# G32R501 register map
Vendor: Geehy Semiconductor Co., Ltd.; Series: G32R5; File version: 1.0
CPU: CM55 r0p1, little endian, MPU, FPU, double-precision FPU, DSP, VTOR, 4 interrupt priority bits
Registers are 32-bit, read-write, reset 0x0 unless marked. A register's access mark holds for its fields unless they carry their own. Offsets are from the block's base; [hi:lo] are bit positions; {n}, {i} and the like mark numbered series.

## PWM_SYNC_SOC
Base 0x40030C80
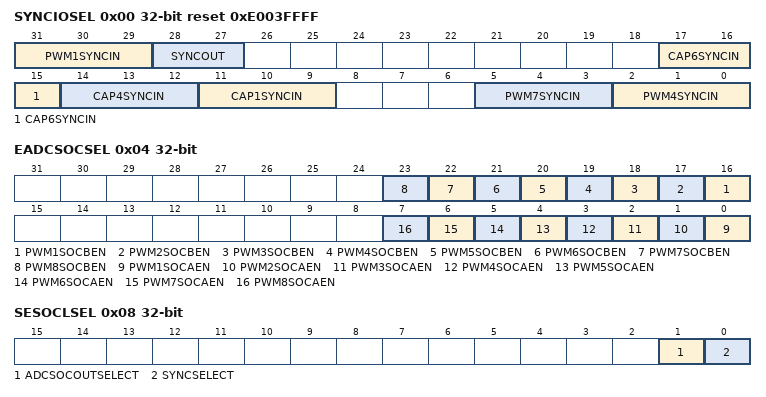
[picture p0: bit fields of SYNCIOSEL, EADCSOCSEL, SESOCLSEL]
0x00 SYNCIOSEL reset 0xE003FFFF
  [31:29] PWM1SYNCIN — PWM1 Sync Input Source Select
  [28:27] SYNCOUT — Sync Output Source Select
  [17:15] CAP6SYNCIN — CAP6 Sync Input Source Select
  [14:12] CAP4SYNCIN — CAP4 Sync Input Source Select
  [11:9] CAP1SYNCIN — CAP1 Sync Input Source Select
  [5:3] PWM7SYNCIN — PWM7 Sync Input Source Select
  [2:0] PWM4SYNCIN — PWM4 Sync Input Source Select
0x04 EADCSOCSEL
  [n+15] PWM{n}SOCBEN (n=1..8) — PWM{n} SOCB Output Source Select
  [n-1] PWM{n}SOCAEN (n=1..8) — PWM{n} SOCA Output Source Select
0x08 SESOCLSEL
  [1] ADCSOCOUTSELECT — EADCSOCSEL Lock
  [0] SYNCSELECT — SIOSEL Lock

## CAP1 — Enhanced capture (CAP) module
Base 0x40002000
Same registers: CAP2 0x40002400, CAP3 0x40002800, CAP4 0x40002C00, CAP5 0x40003000, CAP6 0x40003400, CAP7 0x40003800
0x00 TSCTR — Time-Stamp Counter
  [31:0] TSCTR — Active 32-bit counter register that is used as the capture time-base HR mode
0x04 CTRPHS — Counter Phase Offset Value Register
  [31:0] CTRPHS — Counter phase value register that can be programmed for phase lag/lead
{0x4+4i} CAP{i} (i=1..4) — Capture {i} Register
0x24 ECCTL0 reset 0x7F — Capture Control Register 0
  [6:0] INPUTSEL — Capture input source select bits
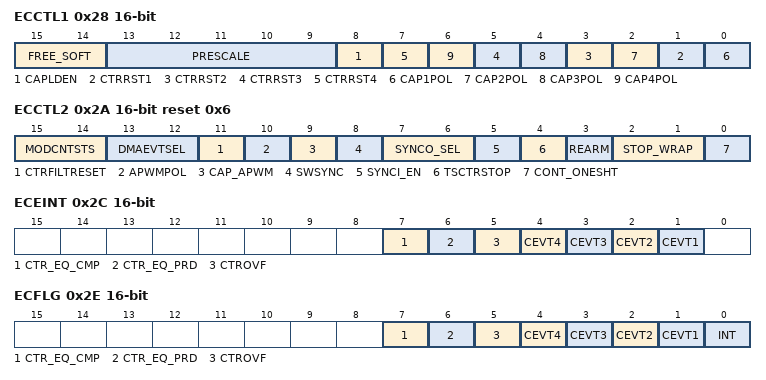
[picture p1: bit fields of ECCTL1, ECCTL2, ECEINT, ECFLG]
0x28 ECCTL1 16-bit — Capture Control Register 1
  [15:14] FREE_SOFT — Emulation Control
  [13:9] PRESCALE — Event Filter prescale select
  [8] CAPLDEN — Enable loading of CAP1-4 registers on a capture event
  [2n-1] CTRRST{n} (n=1..4) — Counter Reset on Capture Event {n}
  [2n-2] CAP{n}POL (n=1..4) — Capture Event {n} Polarity select
0x2A ECCTL2 16-bit access per field reset 0x6 — Capture Control Register 2
  [15:14] MODCNTSTS ro — This bit field reads current status on modulo counter
  [13:12] DMAEVTSEL rw — DMA event select
  [11] CTRFILTRESET rw — Reset Bit
  [10] APWMPOL rw — APWM output polarity select
  [9] CAP_APWM rw — CAP/APWM operating mode select
  [8] SWSYNC rw — Software-forced Counter (TSCTR) Synchronizer
  [7:6] SYNCO_SEL rw — Sync-Out Select
  [5] SYNCI_EN rw — Counter (TSCTR) Sync_In select mode
  [4] TSCTRSTOP rw — Time Stamp (TSCTR) Counter Stop (freeze) Control
  [3] REARM rw — Re-Arming Control
  [2:1] STOP_WRAP rw — Stop value for one-shot mode, Wrap value for continuous
  [0] CONT_ONESHT rw — Continuous or one-sho mode control (applicable only in capture mode)
0x2C ECEINT 16-bit — Capture Interrupt Enable Register
  [7] CTR_EQ_CMP — Counter Equal Compare Interrupt Enable
  [6] CTR_EQ_PRD — Counter Equal Period Interrupt Enable
  [5] CTROVF — Counter Overflow Interrupt Enable
  [n] CEVT{n} (n=1..4) — Capture Event {n} Interrupt Enable
0x2E ECFLG 16-bit ro — Capture Interrupt Flag Register
  [7] CTR_EQ_CMP — Counter Equal Compare Interrupt Flag
  [6] CTR_EQ_PRD — Counter Equal Period Interrupt Flag
  [5] CTROVF — Counter Overflow Interrupt Flag
  [n] CEVT{n} (n=1..4) — Capture Event {n} Interrupt Flag
  [0] INT — Global Interrupt Status Flag
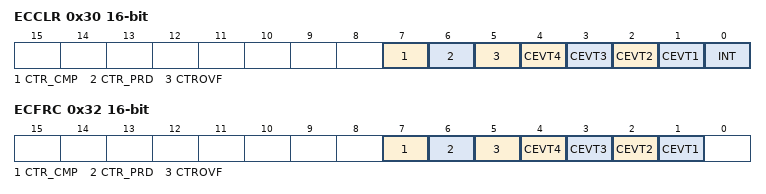
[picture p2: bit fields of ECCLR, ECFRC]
0x30 ECCLR 16-bit — Capture Interrupt Clear Register
  [7] CTR_CMP — Counter Equal Compare Status Clear
  [6] CTR_PRD — Counter Equal Period Status Clear
  [5] CTROVF — Counter Overflow Status Clear
  [n] CEVT{n} (n=1..4) — Capture Event {n} Status Clear
  [0] INT — Global Interrupt Status Clear
0x32 ECFRC 16-bit — Capture Interrupt Force Register
  [7] CTR_CMP — Force Counter Equal Compare Interrupt
  [6] CTR_PRD — Force Capture Event 2
  [5] CTROVF — Force Counter Overflow Interrupt
  [n] CEVT{n} (n=1..4) — Force Capture Event {n} Interrupt

## HRCAP6 — Enhanced capture (CAP) module
Base 0x40003440
Same registers: HRCAP7 0x40003840
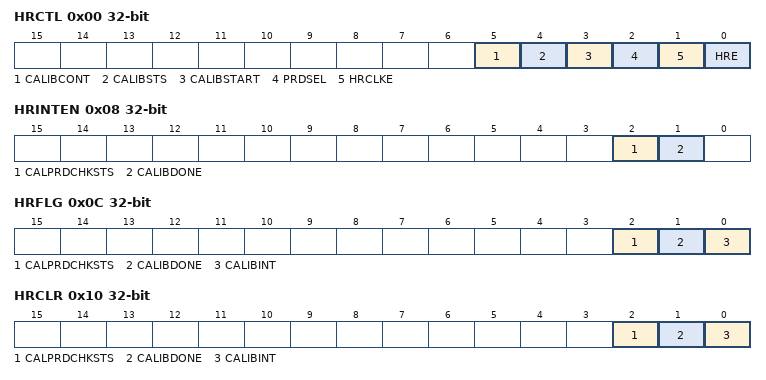
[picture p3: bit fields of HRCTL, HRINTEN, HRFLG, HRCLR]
0x00 HRCTL — High-Res Control Register
  [5] CALIBCONT — Continuous mode Calibration Select Bit
  [4] CALIBSTS — Calibration status Bit
  [3] CALIBSTART — Calibration start Bit
  [2] PRDSEL — Calibration Period Match Select Bit
  [1] HRCLKE — High Resolution Clock Enable Bit
  [0] HRE — High Resolution Enable Bit
0x04 RSVD_HRCAP_0x4 ro — Reserved
0x08 HRINTEN — High-Res Calibration Interrupt Enable Register
  [2] CALPRDCHKSTS — Calibration Period Check status Interrupt Enable
  [1] CALIBDONE — Calibration done Interrupt Enable
0x0C HRFLG ro — High-Res Calibration Interrupt Flag Register
  [2] CALPRDCHKSTS — Calibration period check status Flag Bit
  [1] CALIBDONE — Calibration done Interrupt Flag Bit
  [0] CALIBINT — Global calibration Interrupt Status Flag
0x10 HRCLR — High-Res Calibration Interrupt Clear Register
  [2] CALPRDCHKSTS — Clear Calibration period check status Flag Bit
  [1] CALIBDONE — Clear Calibration done Interrupt Flag
  [0] CALIBINT — Clear Global calibration Interrupt Flag
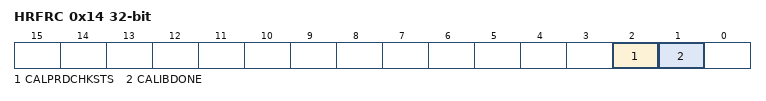
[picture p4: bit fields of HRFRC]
0x14 HRFRC — High-Res Calibration Interrupt Force Register
  [2] CALPRDCHKSTS — Force CALPRDCHKSTS flag
  [1] CALIBDONE — Force CALIBDONE flag
0x18 HRCALPRD reset 0x3FFFFF — High-Res Calibration Period Register
  [31:0] PRD — Register to program calibration period
0x1C HRSYSCLKCTR ro — High-Res Calibration SYSCLK Counter Register
  [31:0] HRSYSCLKCTR — Current SYSCLK counter value
0x20 HRSYSCLKCAP ro — High-Res Calibration SYSCLK Capture Register
  [31:0] HRSYSCLKCAP — HRSYSCLKCTR is captures into this register at end of calibration cycle
0x24 HRCLKCTR ro reset 0x6 — Capture Control Register 2
  [31:0] HRCLKCTR — Current HRCLK counter value
0x28 HRCLKCAP — HRCLKCNT captures
  [31:0] HRCLKCAP — HRCLKCTR is captures into this register at end of calibration cycle
